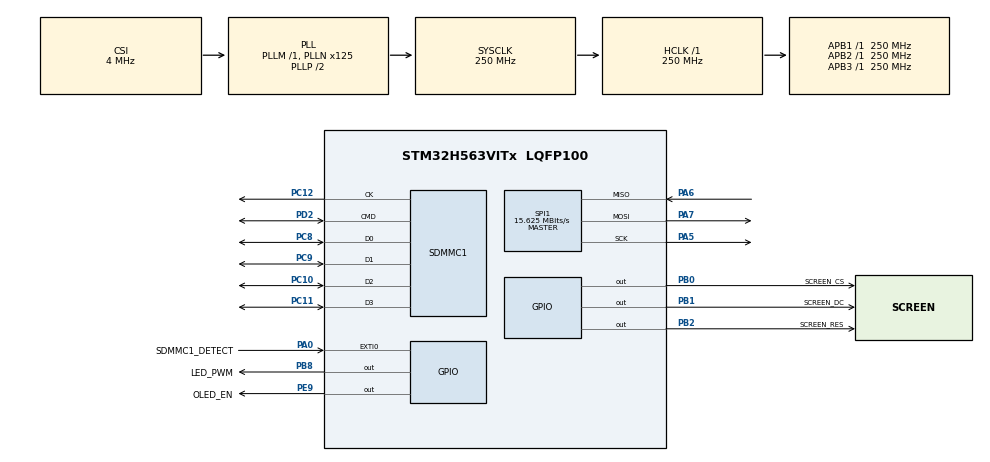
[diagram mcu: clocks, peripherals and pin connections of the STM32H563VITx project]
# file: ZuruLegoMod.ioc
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BOOTPATH.BootPathName=LEGACY
BOOTPATH.UserSelectedBootPath=LEGACY
CORTEX_M33_NS.userName=CORTEX_M33
FILEX.FX_SD_INTERFACE=1
Mcu.Family=STM32H5
Mcu.Name=STM32H563VITx
Mcu.Package=LQFP100
NVIC.EXTI0_IRQn=true\:1\:0\:true\:false\:true\:true\:true\:true
NVIC.PriorityGroup=NVIC_PRIORITYGROUP_4
NVIC.SDMMC1_IRQn=true\:1\:0\:true\:false\:true\:true\:true\:true
PA0.GPIO_Label=SDMMC1_DETECT
PA0.GPIO_ModeDefaultEXTI=GPIO_MODE_IT_RISING_FALLING
PA0.Signal=GPXTI0
PA13(JTMS/SWDIO).Mode=Trace_Asynchronous_SW
PA13(JTMS/SWDIO).Signal=DEBUG_JTMS-SWDIO
PA14(JTCK/SWCLK).Mode=Trace_Asynchronous_SW
PA14(JTCK/SWCLK).Signal=DEBUG_JTCK-SWCLK
PA5.Mode=Full_Duplex_Master
PA5.Signal=SPI1_SCK
PA6.Mode=Full_Duplex_Master
PA6.Signal=SPI1_MISO
PA7.Mode=Full_Duplex_Master
PA7.Signal=SPI1_MOSI
PB0.GPIO_Label=SCREEN_CS
PB0.Signal=GPIO_Output
PB1.GPIO_Label=SCREEN_DC
PB1.Signal=GPIO_Output
PB2.GPIO_Label=SCREEN_RES
PB2.Signal=GPIO_Output
PB3(JTDO/TRACESWO).Mode=Trace_Asynchronous_SW
PB3(JTDO/TRACESWO).Signal=DEBUG_JTDO-SWO
PB8.GPIO_FM8=SBS_FASTMODEPLUS_PB8
PB8.GPIO_Label=LED_PWM
PB8.GPIO_PuPd=GPIO_PULLDOWN
PB8.GPIO_Speed=GPIO_SPEED_FREQ_VERY_HIGH
PB8.Signal=GPIO_Output
PC10.Mode=SD_4_bits_Wide_bus
PC10.Signal=SDMMC1_D2
PC11.Mode=SD_4_bits_Wide_bus
PC11.Signal=SDMMC1_D3
PC12.Mode=SD_4_bits_Wide_bus
PC12.Signal=SDMMC1_CK
PC14-OSC32_IN(OSC32_IN).Mode=LSE-External-Oscillator
PC14-OSC32_IN(OSC32_IN).Signal=RCC_OSC32_IN
PC15-OSC32_OUT(OSC32_OUT).Mode=LSE-External-Oscillator
PC15-OSC32_OUT(OSC32_OUT).Signal=RCC_OSC32_OUT
PC8.Mode=SD_4_bits_Wide_bus
PC8.Signal=SDMMC1_D0
PC9.Mode=SD_4_bits_Wide_bus
PC9.Signal=SDMMC1_D1
PD2.Mode=SD_4_bits_Wide_bus
PD2.Signal=SDMMC1_CMD
PE9.GPIO_Label=OLED_EN
PE9.GPIO_PuPd=GPIO_PULLDOWN
PE9.Signal=GPIO_Output
PH0-OSC_IN(PH0).Mode=HSE-External-Oscillator
PH0-OSC_IN(PH0).Signal=RCC_OSC_IN
PH1-OSC_OUT(PH1).Mode=HSE-External-Oscillator
PH1-OSC_OUT(PH1).Signal=RCC_OSC_OUT
ProjectManager.HeapSize=0x200
ProjectManager.StackSize=0x400
ProjectManager.TargetToolchain=Makefile
RCC.ADCFreq_Value=250000000
RCC.AHBFreq_Value=250000000
RCC.APB1Freq_Value=250000000
RCC.APB1TimFreq_Value=250000000
RCC.APB2Freq_Value=250000000
RCC.APB2TimFreq_Value=250000000
RCC.APB3Freq_Value=250000000
RCC.CSI_VALUE=4000000
RCC.CortexFreq_Value=250000000
RCC.EPOD_VALUE=4000000
RCC.HCLKFreq_Value=250000000
RCC.HSE_VALUE=25000000
RCC.HSI48_VALUE=48000000
RCC.HSI_VALUE=64000000
RCC.LSIRC_VALUE=32000
RCC.PLL2FRACN=0
RCC.PLL3FRACN=0
RCC.PLLFRACN=0
RCC.PLLN=125
RCC.SYSCLKFreq_VALUE=250000000
RCC.SYSCLKSource=RCC_SYSCLKSOURCE_PLLCLK
RCC.USBFreq_Value=48000000
RCC.VCOOutputFreq_Value=500000000
SDMMC1.ClockDiv=0x01
SPI1.BaudRatePrescaler=SPI_BAUDRATEPRESCALER_16
SPI1.CalculateBaudRate=15.625 MBits/s
SPI1.DataSize=SPI_DATASIZE_8BIT
SPI1.Direction=SPI_DIRECTION_2LINES
SPI1.Mode=SPI_MODE_MASTER
SPI1.VirtualType=VM_MASTER
VP_BOOTPATH_VS_BOOTPATH.Mode=BP_Activate
VP_CORTEX_M33_NS_VS_Hclk.Mode=Hclk_Mode
VP_FILEX_VS_FileOoSystemJjFileXJjCore.Mode=FileX_Core
VP_FILEX_VS_SDOointerface.Mode=SD_interface
VP_ICACHE_VS_ENABLE_ICACHE_MEMORY.Mode=Memoryregions
VP_MEMORYMAP_VS_MEMORYMAP.Mode=CurAppReg
VP_PWR_VS_LPOM.Mode=PowerOptimisation
VP_PWR_VS_SECSignals.Mode=Security/Privilege
board=custom

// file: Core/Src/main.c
/* USER CODE BEGIN Header */
/**
  ******************************************************************************
  * @file           : main.c
  * @brief          : Main program body
  ******************************************************************************
  * @attention
  *
  * Copyright (c) 2025 STMicroelectronics.
  * All rights reserved.
  *
  * This software is licensed under terms that can be found in the LICENSE file
  * in the root directory of this software component.
  * If no LICENSE file comes with this software, it is provided AS-IS.
  *
  ******************************************************************************
  */
/* USER CODE END Header */
#include "main.h"
#include "app_filex.h"
#include "icache.h"
#include "memorymap.h"
#include "sdmmc.h"
#include "spi.h"
#include "gpio.h"

/* USER CODE BEGIN Includes */
#include "nhd_1_8_160128B.h"
/* USER CODE END Includes */

void SystemClock_Config(void);

int main(void)
{

  /* MCU Configuration--------------------------------------------------------*/

  /* Reset of all peripherals, Initializes the Flash interface and the Systick. */
  HAL_Init();

  /* Configure the system clock */
  SystemClock_Config();

  /* Initialize all configured peripherals */
  MX_GPIO_Init();
  MX_ICACHE_Init();
  MX_SDMMC1_SD_Init();
  MX_SPI1_Init();
  MX_FileX_Init();
  /* USER CODE BEGIN 2 */
  nhd_160128b_init();
  nhd_160128b_FillScreen(0x0000);
  /* USER CODE END 2 */

  /* Infinite loop */
  /* USER CODE BEGIN WHILE */
  init_lego_fsm();
  while (1)
  {
    lego_fsm();
    /* USER CODE END WHILE */

  }
}

void SystemClock_Config(void)
{
  RCC_OscInitTypeDef RCC_OscInitStruct = {0};
  RCC_ClkInitTypeDef RCC_ClkInitStruct = {0};

  /** Configure the main internal regulator output voltage
  */
  __HAL_PWR_VOLTAGESCALING_CONFIG(PWR_REGULATOR_VOLTAGE_SCALE0);

  while(!__HAL_PWR_GET_FLAG(PWR_FLAG_VOSRDY)) {}

  /** Initializes the RCC Oscillators according to the specified parameters
  * in the RCC_OscInitTypeDef structure.
  */
  RCC_OscInitStruct.OscillatorType = RCC_OSCILLATORTYPE_CSI;
  RCC_OscInitStruct.CSIState = RCC_CSI_ON;
  RCC_OscInitStruct.CSICalibrationValue = RCC_CSICALIBRATION_DEFAULT;
  RCC_OscInitStruct.PLL.PLLState = RCC_PLL_ON;
  RCC_OscInitStruct.PLL.PLLSource = RCC_PLL1_SOURCE_CSI;
  RCC_OscInitStruct.PLL.PLLM = 1;
  RCC_OscInitStruct.PLL.PLLN = 125;
  RCC_OscInitStruct.PLL.PLLP = 2;
  RCC_OscInitStruct.PLL.PLLQ = 2;
  RCC_OscInitStruct.PLL.PLLR = 2;
  RCC_OscInitStruct.PLL.PLLRGE = RCC_PLL1_VCIRANGE_2;
  RCC_OscInitStruct.PLL.PLLVCOSEL = RCC_PLL1_VCORANGE_WIDE;
  RCC_OscInitStruct.PLL.PLLFRACN = 0;
  if (HAL_RCC_OscConfig(&RCC_OscInitStruct) != HAL_OK)
  {
    Error_Handler();
  }

  /** Initializes the CPU, AHB and APB buses clocks
  */
  RCC_ClkInitStruct.ClockType = RCC_CLOCKTYPE_HCLK|RCC_CLOCKTYPE_SYSCLK
                              |RCC_CLOCKTYPE_PCLK1|RCC_CLOCKTYPE_PCLK2
                              |RCC_CLOCKTYPE_PCLK3;
  RCC_ClkInitStruct.SYSCLKSource = RCC_SYSCLKSOURCE_PLLCLK;
  RCC_ClkInitStruct.AHBCLKDivider = RCC_SYSCLK_DIV1;
  RCC_ClkInitStruct.APB1CLKDivider = RCC_HCLK_DIV1;
  RCC_ClkInitStruct.APB2CLKDivider = RCC_HCLK_DIV1;
  RCC_ClkInitStruct.APB3CLKDivider = RCC_HCLK_DIV1;

  if (HAL_RCC_ClockConfig(&RCC_ClkInitStruct, FLASH_LATENCY_5) != HAL_OK)
  {
    Error_Handler();
  }

  /** Configure the programming delay
  */
  __HAL_FLASH_SET_PROGRAM_DELAY(FLASH_PROGRAMMING_DELAY_2);
}

void Error_Handler(void)
{
  __disable_irq();
  while (1)
  {
  }
}
